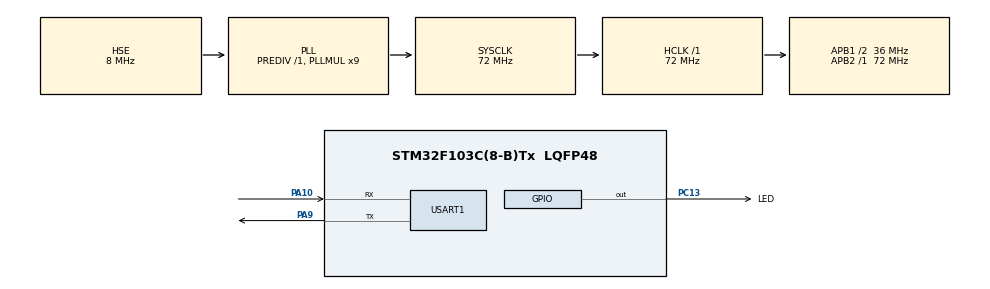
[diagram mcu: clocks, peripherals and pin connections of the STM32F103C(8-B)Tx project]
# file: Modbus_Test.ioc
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Dma.Request0=USART1_RX
Dma.Request1=USART1_TX
Dma.USART1_RX.0.Direction=DMA_PERIPH_TO_MEMORY
Dma.USART1_RX.0.Instance=DMA1_Channel5
Dma.USART1_RX.0.MemDataAlignment=DMA_MDATAALIGN_BYTE
Dma.USART1_RX.0.MemInc=DMA_MINC_ENABLE
Dma.USART1_RX.0.Mode=DMA_NORMAL
Dma.USART1_RX.0.PeriphDataAlignment=DMA_PDATAALIGN_BYTE
Dma.USART1_RX.0.PeriphInc=DMA_PINC_DISABLE
Dma.USART1_RX.0.Priority=DMA_PRIORITY_LOW
Dma.USART1_TX.1.Direction=DMA_MEMORY_TO_PERIPH
Dma.USART1_TX.1.Instance=DMA1_Channel4
Dma.USART1_TX.1.MemDataAlignment=DMA_MDATAALIGN_BYTE
Dma.USART1_TX.1.MemInc=DMA_MINC_ENABLE
Dma.USART1_TX.1.Mode=DMA_NORMAL
Dma.USART1_TX.1.PeriphDataAlignment=DMA_PDATAALIGN_BYTE
Dma.USART1_TX.1.PeriphInc=DMA_PINC_DISABLE
Dma.USART1_TX.1.Priority=DMA_PRIORITY_LOW
FREERTOS.BinarySemaphores01=UsartRecieveSem,Dynamic,NULL
FREERTOS.Tasks01=ModbusTask,24,512,StartModbusTask,Default,NULL,Dynamic,NULL,NULL
FREERTOS.configMINIMAL_STACK_SIZE=512
FREERTOS.configUSE_NEWLIB_REENTRANT=1
Mcu.Family=STM32F1
Mcu.Name=STM32F103C(8-B)Tx
Mcu.Package=LQFP48
NVIC.DMA1_Channel4_IRQn=true\:5\:0\:false\:false\:true\:true\:false\:true\:true
NVIC.DMA1_Channel5_IRQn=true\:5\:0\:false\:false\:true\:true\:false\:true\:true
NVIC.PriorityGroup=NVIC_PRIORITYGROUP_4
NVIC.TIM4_IRQn=true\:15\:0\:false\:false\:true\:false\:false\:true\:true
NVIC.TimeBase=TIM4_IRQn
NVIC.TimeBaseIP=TIM4
NVIC.USART1_IRQn=true\:5\:0\:false\:false\:true\:true\:true\:true\:true
PA10.Mode=Asynchronous
PA10.Signal=USART1_RX
PA13.Mode=Trace_Asynchronous_SW
PA13.Signal=SYS_JTMS-SWDIO
PA14.Mode=Trace_Asynchronous_SW
PA14.Signal=SYS_JTCK-SWCLK
PA9.Mode=Asynchronous
PA9.Signal=USART1_TX
PB3.Mode=Trace_Asynchronous_SW
PB3.Signal=SYS_JTDO-TRACESWO
PC13-TAMPER-RTC.GPIO_Label=LED
PC13-TAMPER-RTC.GPIO_Speed=GPIO_SPEED_FREQ_HIGH
PC13-TAMPER-RTC.Signal=GPIO_Output
PD0-OSC_IN.Mode=HSE-External-Oscillator
PD0-OSC_IN.Signal=RCC_OSC_IN
PD1-OSC_OUT.Mode=HSE-External-Oscillator
PD1-OSC_OUT.Signal=RCC_OSC_OUT
ProjectManager.HeapSize=0x200
ProjectManager.StackSize=0x400
ProjectManager.TargetToolchain=STM32CubeIDE
RCC.AHBFreq_Value=72000000
RCC.APB1CLKDivider=RCC_HCLK_DIV2
RCC.APB1Freq_Value=36000000
RCC.APB1TimFreq_Value=72000000
RCC.APB2Freq_Value=72000000
RCC.APB2TimFreq_Value=72000000
RCC.HCLKFreq_Value=72000000
RCC.PLLMUL=RCC_PLL_MUL9
RCC.PLLSourceVirtual=RCC_PLLSOURCE_HSE
RCC.SYSCLKFreq_VALUE=72000000
RCC.SYSCLKSource=RCC_SYSCLKSOURCE_PLLCLK
RCC.USBFreq_Value=72000000
USART1.VirtualMode=VM_ASYNC
VP_FREERTOS_VS_CMSIS_V2.Mode=CMSIS_V2
VP_SYS_VS_tim4.Mode=TIM4
board=custom

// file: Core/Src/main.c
/* USER CODE BEGIN Header */
/**
  ******************************************************************************
  * @file           : main.c
  * @brief          : Main program body
  ******************************************************************************
  * @attention
  *
  * Copyright (c) 2024 STMicroelectronics.
  * All rights reserved.
  *
  * This software is licensed under terms that can be found in the LICENSE file
  * in the root directory of this software component.
  * If no LICENSE file comes with this software, it is provided AS-IS.
  *
  ******************************************************************************
  */
/* USER CODE END Header */
#include "main.h"
#include "cmsis_os.h"

/* USER CODE BEGIN Includes */
#include <modbus.h>
/* USER CODE END Includes */

UART_HandleTypeDef huart1;
DMA_HandleTypeDef hdma_usart1_rx;
DMA_HandleTypeDef hdma_usart1_tx;

/* Definitions for ModbusTask */
osThreadId_t ModbusTaskHandle;
const osThreadAttr_t ModbusTask_attributes = {
  .name = "ModbusTask",
  .stack_size = 512 * 4,
  .priority = (osPriority_t) osPriorityNormal,
};
/* Definitions for UsartRecieveSem */
osSemaphoreId_t UsartRecieveSemHandle;
const osSemaphoreAttr_t UsartRecieveSem_attributes = {
  .name = "UsartRecieveSem"
};

void SystemClock_Config(void);
static void MX_GPIO_Init(void);
static void MX_DMA_Init(void);
static void MX_USART1_UART_Init(void);
void StartModbusTask(void *argument);

/* USER CODE BEGIN 0 */
uint8_t dataRX;
/* USER CODE END 0 */

int main(void)
{

  /* MCU Configuration--------------------------------------------------------*/

  /* Reset of all peripherals, Initializes the Flash interface and the Systick. */
  HAL_Init();

  /* Configure the system clock */
  SystemClock_Config();

  /* Initialize all configured peripherals */
  MX_GPIO_Init();
  MX_DMA_Init();
  MX_USART1_UART_Init();

  /* Init scheduler */
  osKernelInitialize();

  /* Create the semaphores(s) */
  /* creation of UsartRecieveSem */
  UsartRecieveSemHandle = osSemaphoreNew(1, 0, &UsartRecieveSem_attributes);

  /* Create the thread(s) */
  /* creation of ModbusTask */
  ModbusTaskHandle = osThreadNew(StartModbusTask, NULL, &ModbusTask_attributes);

  /* Start scheduler */
  osKernelStart();

  /* We should never get here as control is now taken by the scheduler */

  /* Infinite loop */
  while (1)
  {

  }
}

void SystemClock_Config(void)
{
  RCC_OscInitTypeDef RCC_OscInitStruct = {0};
  RCC_ClkInitTypeDef RCC_ClkInitStruct = {0};

  /** Initializes the RCC Oscillators according to the specified parameters
  * in the RCC_OscInitTypeDef structure.
  */
  RCC_OscInitStruct.OscillatorType = RCC_OSCILLATORTYPE_HSE;
  RCC_OscInitStruct.HSEState = RCC_HSE_ON;
  RCC_OscInitStruct.HSEPredivValue = RCC_HSE_PREDIV_DIV1;
  RCC_OscInitStruct.HSIState = RCC_HSI_ON;
  RCC_OscInitStruct.PLL.PLLState = RCC_PLL_ON;
  RCC_OscInitStruct.PLL.PLLSource = RCC_PLLSOURCE_HSE;
  RCC_OscInitStruct.PLL.PLLMUL = RCC_PLL_MUL9;
  if (HAL_RCC_OscConfig(&RCC_OscInitStruct) != HAL_OK)
  {
    Error_Handler();
  }

  /** Initializes the CPU, AHB and APB buses clocks
  */
  RCC_ClkInitStruct.ClockType = RCC_CLOCKTYPE_HCLK|RCC_CLOCKTYPE_SYSCLK
                              |RCC_CLOCKTYPE_PCLK1|RCC_CLOCKTYPE_PCLK2;
  RCC_ClkInitStruct.SYSCLKSource = RCC_SYSCLKSOURCE_PLLCLK;
  RCC_ClkInitStruct.AHBCLKDivider = RCC_SYSCLK_DIV1;
  RCC_ClkInitStruct.APB1CLKDivider = RCC_HCLK_DIV2;
  RCC_ClkInitStruct.APB2CLKDivider = RCC_HCLK_DIV1;

  if (HAL_RCC_ClockConfig(&RCC_ClkInitStruct, FLASH_LATENCY_2) != HAL_OK)
  {
    Error_Handler();
  }
}

static void MX_USART1_UART_Init(void)
{

  huart1.Instance = USART1;
  huart1.Init.BaudRate = 115200;
  huart1.Init.WordLength = UART_WORDLENGTH_8B;
  huart1.Init.StopBits = UART_STOPBITS_1;
  huart1.Init.Parity = UART_PARITY_NONE;
  huart1.Init.Mode = UART_MODE_TX_RX;
  huart1.Init.HwFlowCtl = UART_HWCONTROL_NONE;
  huart1.Init.OverSampling = UART_OVERSAMPLING_16;
  if (HAL_UART_Init(&huart1) != HAL_OK)
  {
    Error_Handler();
  }

}

static void MX_DMA_Init(void)
{

  /* DMA controller clock enable */
  __HAL_RCC_DMA1_CLK_ENABLE();

  /* DMA interrupt init */
  /* DMA1_Channel4_IRQn interrupt configuration */
  HAL_NVIC_SetPriority(DMA1_Channel4_IRQn, 5, 0);
  HAL_NVIC_EnableIRQ(DMA1_Channel4_IRQn);
  /* DMA1_Channel5_IRQn interrupt configuration */
  HAL_NVIC_SetPriority(DMA1_Channel5_IRQn, 5, 0);
  HAL_NVIC_EnableIRQ(DMA1_Channel5_IRQn);

}

static void MX_GPIO_Init(void)
{
  GPIO_InitTypeDef GPIO_InitStruct = {0};

  /* GPIO Ports Clock Enable */
  __HAL_RCC_GPIOC_CLK_ENABLE();
  __HAL_RCC_GPIOD_CLK_ENABLE();
  __HAL_RCC_GPIOA_CLK_ENABLE();
  __HAL_RCC_GPIOB_CLK_ENABLE();

  /*Configure GPIO pin Output Level */
  HAL_GPIO_WritePin(LED_GPIO_Port, LED_Pin, GPIO_PIN_RESET);

  /*Configure GPIO pin : LED_Pin */
  GPIO_InitStruct.Pin = LED_Pin;
  GPIO_InitStruct.Mode = GPIO_MODE_OUTPUT_PP;
  GPIO_InitStruct.Pull = GPIO_NOPULL;
  GPIO_InitStruct.Speed = GPIO_SPEED_FREQ_HIGH;
  HAL_GPIO_Init(LED_GPIO_Port, &GPIO_InitStruct);

}

void StartModbusTask(void *argument)
{
  /* USER CODE BEGIN 5 */
	modbus_t *ctx = NULL;
	uint8_t req[180];
	int rc;
	// Создаем структуру модбас регистров
	modbus_mapping_t *modbus_map;
	modbus_map = modbus_mapping_new(10, 0, 0x15, 0);  // обнуляем значения
	modbus_map->tab_registers[1] = 0;
	ctx = modbus_new_rtu("COM1", 115200, 0, 8, 1);
	modbus_set_slave(ctx, 1);
	modbus_set_byte_timeout(ctx, 0, 0);
	modbus_set_response_timeout(ctx, 0, 0);
	modbus_connect(ctx);
	modbus_flush(ctx);
  /* Infinite loop */
  for(;;)
  {
	rc = modbus_receive(ctx, req);
		if (rc == 8)
		{
			modbus_reply(ctx, req, rc, modbus_map);
		}
		modbus_map->tab_registers[1]+=1;
    osDelay(1);
  }
  /* USER CODE END 5 */
}

void HAL_TIM_PeriodElapsedCallback(TIM_HandleTypeDef *htim)
{
  if (htim->Instance == TIM4) {
    HAL_IncTick();
  }
}

void Error_Handler(void)
{
  __disable_irq();
  while (1)
  {
  }
}
